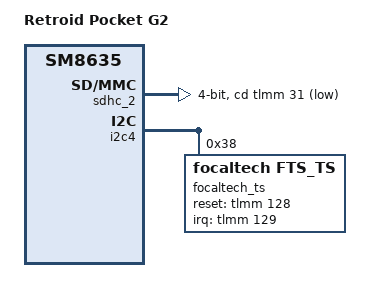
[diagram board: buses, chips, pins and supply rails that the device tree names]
// SPDX-License-Identifier: BSD-3-Clause
/*
 * Copyright (C) 2026 Jean-Ralphio Saperstein
 */

/dts-v1/;

#include "sm8635.dtsi"

/ {
	model = "Retroid Pocket G2";
	compatible = "retroidpocket,pocket-g2", "qcom,sm8635", "qcom,mtp";

	aliases {
		serial0 = &uart_g2;
		mmc1 = &sdhc_2;
	};

	chosen {
		stdout-path = "serial0:115200n8";
		bootargs = "root=/dev/mmcblk1p1 rootwait quiet console=ttyMSM0,115200n8";
	};
};

&sdhc_2 {
	status = "okay";
	bus-width = <4>;
	cd-gpios = <&tlmm 31 GPIO_ACTIVE_LOW>;
	no-mmc;
	no-sdio;
};

&i2c4 {
	focaltech_ts: focaltech@38 {
		compatible = "focaltech,fts_ts";
		reg = <0x38>;
		interrupt-parent = <&tlmm>;
		interrupts = <129 IRQ_TYPE_EDGE_FALLING>;
		reset-gpios = <&tlmm 128 GPIO_ACTIVE_HIGH>;
		status = "okay";
	};
};
